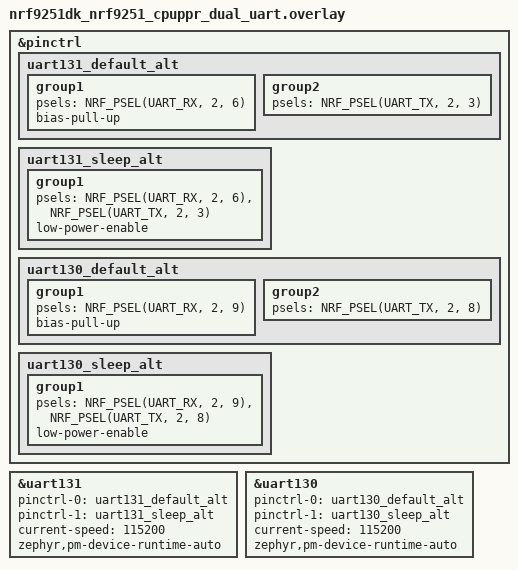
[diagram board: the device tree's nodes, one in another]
/*
 * Copyright (c) 2026 Nordic Semiconductor ASA
 *
 * SPDX-License-Identifier: LicenseRef-Nordic-5-Clause
 */

/* Test requires loopbacks:
 * TX1-RX1: P2.03 - P2.09
 * TX2-RX2: P2.06 - P2.08
 */

&pinctrl {
	uart131_default_alt: uart131_default_alt {
		group1 {
			psels = <NRF_PSEL(UART_RX, 2, 6)>;
			bias-pull-up;
		};

		group2 {
			psels = <NRF_PSEL(UART_TX, 2, 3)>;
		};
	};

	uart131_sleep_alt: uart131_sleep_alt {
		group1 {
			psels = <NRF_PSEL(UART_RX, 2, 6)>,
				<NRF_PSEL(UART_TX, 2, 3)>;
			low-power-enable;
		};
	};

	uart130_default_alt: uart130_default_alt {
		group1 {
			psels = <NRF_PSEL(UART_RX, 2, 9)>;
			bias-pull-up;
		};

		group2 {
			psels = <NRF_PSEL(UART_TX, 2, 8)>;
		};
	};

	uart130_sleep_alt: uart130_sleep_alt {
		group1 {
			psels = <NRF_PSEL(UART_RX, 2, 9)>,
				<NRF_PSEL(UART_TX, 2, 8)>;
			low-power-enable;
		};
	};
};

dut: &uart131 {
	status = "okay";
	pinctrl-0 = <&uart131_default_alt>;
	pinctrl-1 = <&uart131_sleep_alt>;
	pinctrl-names = "default", "sleep";
	current-speed = <115200>;
	zephyr,pm-device-runtime-auto;
};

dut_aux: &uart130 {
	status = "okay";
	pinctrl-0 = <&uart130_default_alt>;
	pinctrl-1 = <&uart130_sleep_alt>;
	pinctrl-names = "default", "sleep";
	current-speed = <115200>;
	zephyr,pm-device-runtime-auto;
};
